# AT32A403Axx_v2 register map
Vendor: Keil; Series: AT32A403A; File version: 1.0
CPU: CM4 r0p1, little endian, no MPU, FPU, 4 interrupt priority bits
Registers are 32-bit, read-write, reset 0x0 unless marked. A register's access mark holds for its fields unless they carry their own. Offsets are from the block's base; [hi:lo] are bit positions; {n}, {i} and the like mark numbered series; 'fields as' and 'values as' point back to an identical list.

## CAN1 — Can controller area network
Base 0x40006400
Same registers: CAN2 0x40006800
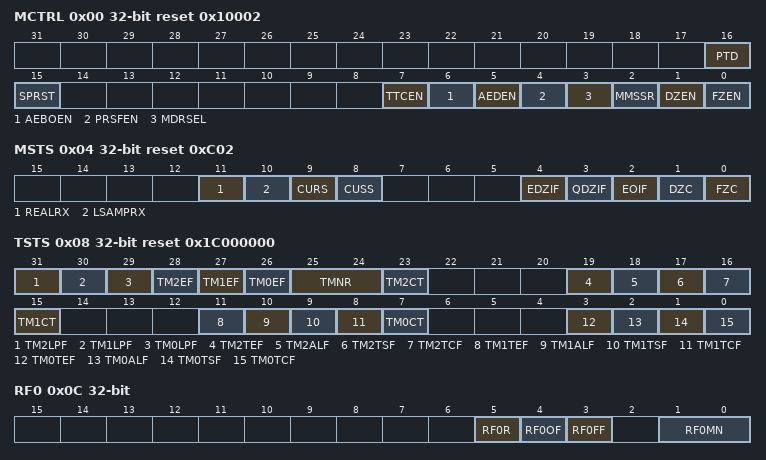
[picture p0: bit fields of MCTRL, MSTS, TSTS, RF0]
0x00 MCTRL reset 0x10002 — Main control register
  [16] PTD — Prohibit transmission when debug
  [15] SPRST — Software partial reset
  [7] TTCEN — Time triggered communication mode enable
  [6] AEBOEN — Automatic exit bus-off enable
  [5] AEDEN — Automatic exit doze mode enable
  [4] PRSFEN — Prohibit retransmission when sending fails enable
  [3] MDRSEL — Message discarding rule select when overflow
  [2] MMSSR — Multiple message sending sequence rule
  [1] DZEN — Doze mode enable
  [0] FZEN — Freeze mode enable
0x04 MSTS reset 0xC02 — Main status register
  [11] REALRX ro — Real time level of RX pin
  [10] LSAMPRX ro — Last sample level of RX pin
  [9] CURS ro — Currently receiving status
  [8] CUSS ro — Currently sending status
  [4] EDZIF — Enter doze mode interrupt flag
  [3] QDZIF — Quit doze mode interrupt flag
  [2] EOIF — Error occur Interrupt flag
  [1] DZC ro — Doze mode confirm
  [0] FZC ro — Freeze mode confirm
0x08 TSTS reset 0x1C000000 — Transmit status register
  [31] TM2LPF ro — Transmit mailbox 2 lowest priority flag
  [30] TM1LPF ro — Transmit mailbox 1 lowest priority flag
  [29] TM0LPF ro — Transmit mailbox 0 lowest priority flag
  [28] TM2EF ro — Transmit mailbox 2 empty flag
  [27] TM1EF ro — Transmit mailbox 1 empty flag
  [26] TM0EF ro — Transmit mailbox 0 empty flag
  [25:24] TMNR ro — Transmit Mailbox number record
  [23] TM2CT — Transmit mailbox 2 cancel transmission
  [19] TM2TEF — Transmit mailbox 2 transmission error flag
  [18] TM2ALF — Transmit mailbox 2 arbitration lost flag
  [17] TM2TSF — Transmit mailbox 2 transmission success flag
  [16] TM2TCF — transmit mailbox 2 transmission complete flag
  [15] TM1CT — Transmit mailbox 1 cancel transmission
  [11] TM1TEF — Transmit mailbox 1 transmission error flag
  [10] TM1ALF — Transmit mailbox 1 arbitration lost flag
  [9] TM1TSF — Transmit mailbox 1 transmission success flag
  [8] TM1TCF — Transmit mailbox 1 transmission complete flag
  [7] TM0CT — Transmit mailbox 0 cancel transmission
  [3] TM0TEF — Transmit mailbox 0 transmission error flag
  [2] TM0ALF — Transmit mailbox 0 arbitration lost flag
  [1] TM0TSF — Transmit mailbox 0 transmission success flag
  [0] TM0TCF — Transmit mailbox 0 transmission complete flag
0x0C RF0 — Receive FIFO 0 register
  [5] RF0R — Receive FIFO 0 release
  [4] RF0OF — Receive FIFO 0 overflow flag
  [3] RF0FF — Receive FIFO 0 full flag
  [1:0] RF0MN ro — Receive FIFO 0 message num
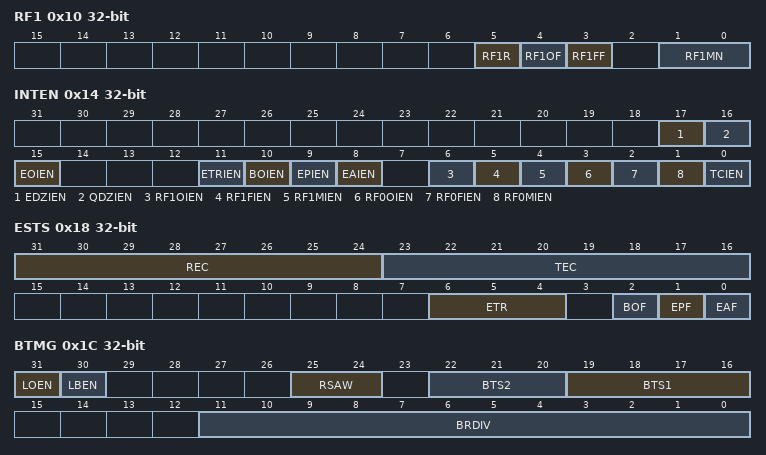
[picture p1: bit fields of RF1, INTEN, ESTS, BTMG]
0x10 RF1 — Receive FIFO 1 register
  [5] RF1R — Receive FIFO 1 release
  [4] RF1OF — Receive FIFO 1 overflow flag
  [3] RF1FF — Receive FIFO 1 full flag
  [1:0] RF1MN ro — Receive FIFO 1 message num
0x14 INTEN — Interrupt enable register
  [17] EDZIEN — Enter doze mode interrupt enable
  [16] QDZIEN — Quit doze mode interrupt enable
  [15] EOIEN — Error occur interrupt enable
  [11] ETRIEN — Error type record interrupt enable
  [10] BOIEN — Bus-off interrupt enable
  [9] EPIEN — Error passive interrupt enable
  [8] EAIEN — Error active interrupt enable
  [6] RF1OIEN — Receive FIFO 1 overflow interrupt enable
  [5] RF1FIEN — Receive FIFO 1 full interrupt enable
  [4] RF1MIEN — FIFO 1 receive message interrupt enable
  [3] RF0OIEN — Receive FIFO 0 overflow interrupt enable
  [2] RF0FIEN — Receive FIFO 0 full interrupt enable
  [1] RF0MIEN — FIFO 0 receive message interrupt enable
  [0] TCIEN — Transmission complete interrupt enable
0x18 ESTS — Error status register
  [31:24] REC ro — Receive error counter
  [23:16] TEC ro — Transmit error counter
  [6:4] ETR — Error type record
  [2] BOF ro — Bus-off flag
  [1] EPF ro — Error passive flag
  [0] EAF ro — Error active flag
0x1C BTMG — Bit timing register
  [31] LOEN — Listen-Only mode
  [30] LBEN — Loop back mode
  [25:24] RSAW — Resynchronization adjust width
  [22:20] BTS2 — Bit time segment 2
  [19:16] BTS1 — Bit time segment 1
  [11:0] BRDIV — Baud rate division
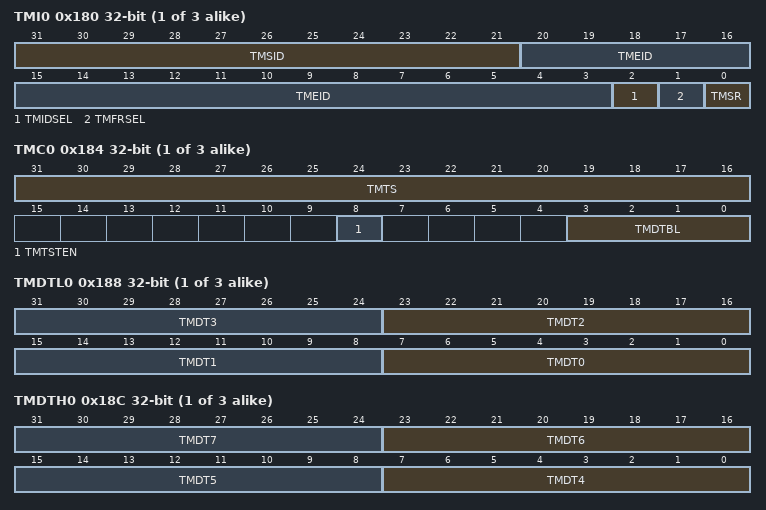
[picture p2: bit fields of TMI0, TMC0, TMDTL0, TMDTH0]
{0x180+0x10*i} TMI{i} (i=0..2) — Transmit mailbox {i} identifier register
  [31:21] TMSID — Transmit mailbox standard identifier or extended identifier high bytes
  [20:3] TMEID — Ttransmit mailbox extended identifier
  [2] TMIDSEL — Transmit mailbox identifier type select
  [1] TMFRSEL — Transmit mailbox frame type select
  [0] TMSR — Transmit mailbox send request
{0x184+0x10*i} TMC{i} (i=0..2) — Transmit mailbox {i} data length and time stamp register
  [31:16] TMTS — Transmit mailbox time stamp
  [8] TMTSTEN — Transmit mailbox time stamp transmit enable
  [3:0] TMDTBL — Transmit mailbox data byte length
{0x188+0x10*i} TMDTL{i} (i=0..2) — Transmit mailbox {i} low byte data register
  [8n+7:8n] TMDT{n} (n=0..3) — Transmit mailbox data byte {n}
{0x18C+0x10*i} TMDTH{i} (i=0..2) — Transmit mailbox {i} high byte data register
  [8n-25:8n-32] TMDT{n} (n=4..7) — Transmit mailbox data byte {n}
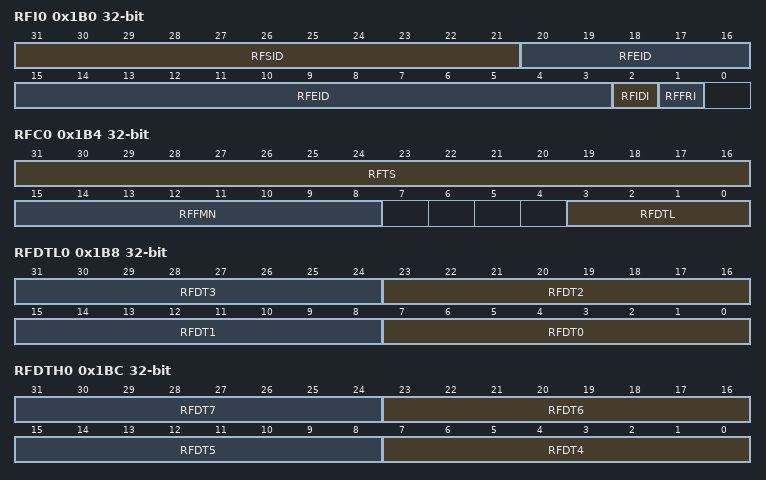
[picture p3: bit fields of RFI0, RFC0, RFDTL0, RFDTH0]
0x1B0 RFI0 ro — Receive FIFO 0 register
  [31:21] RFSID — Receive FIFO standard identifier or receive FIFO extended identifier
  [20:3] RFEID — Receive FIFO extended identifier
  [2] RFIDI — Receive FIFO identifier type indication
  [1] RFFRI — Receive FIFO frame type indication
0x1B4 RFC0 ro — Receive FIFO 0 data length and time stamp register
  [31:16] RFTS — Receive FIFO time stamp
  [15:8] RFFMN — Receive FIFO filter match number
  [3:0] RFDTL — Receive FIFO data length
0x1B8 RFDTL0 ro — Receive FIFO 0 low byte data register
  [8n+7:8n] RFDT{n} (n=0..3) — Receive FIFO data byte {n}
0x1BC RFDTH0 ro — Receive FIFO 0 high byte data register
  [8n-25:8n-32] RFDT{n} (n=4..7) — Receive FIFO data byte {n}
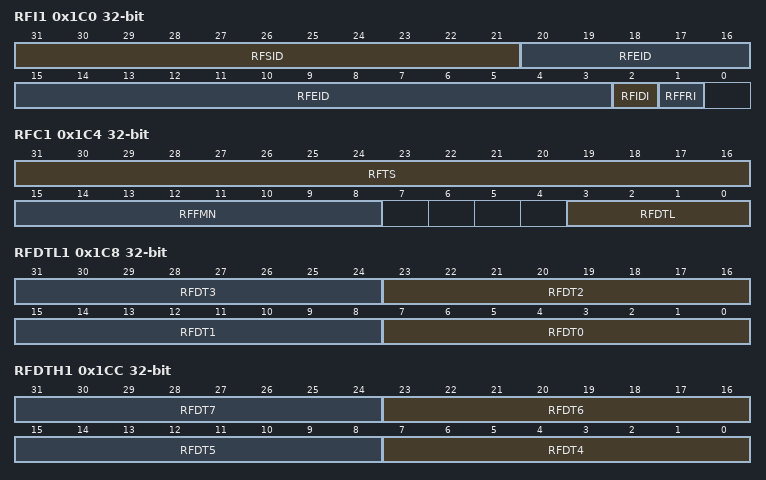
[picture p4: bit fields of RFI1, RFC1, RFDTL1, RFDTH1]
0x1C0 RFI1 ro — Receive FIFO 1 register
  fields as RFI0
0x1C4 RFC1 ro — Receive FIFO 1 data length and time stamp register
  fields as RFC0
0x1C8 RFDTL1 ro — Receive FIFO 1 low byte data register
  [8n+7:8n] RFDT{n} (n=0..3) — Receive FIFO data byte {n}
0x1CC RFDTH1 ro — Receive FIFO 1 high byte data register
  [8n-25:8n-32] RFDT{n} (n=4..7) — Receive FIFO data byte {n}
0x200 FCTRL — Filter control register
  [0] FCS — Filters configure switch
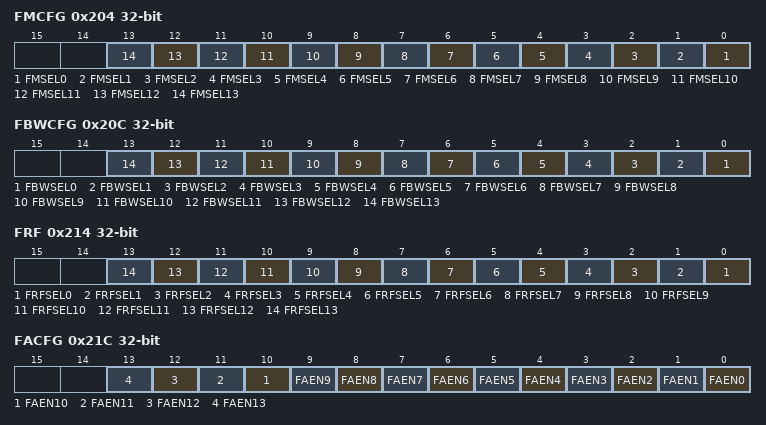
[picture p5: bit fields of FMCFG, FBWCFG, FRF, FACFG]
0x204 FMCFG — Filter mode config register
  [n] FMSEL{n} (n=0..13) — Filter mode select
0x20C FBWCFG — Filter bit width config register
  [n] FBWSEL{n} (n=0..13) — Filter bit width select
0x214 FRF — Filter related FIFO register
  [n] FRFSEL{n} (n=0..13) — Filter relation FIFO select
0x21C FACFG — Filter activate configuration register
  [n] FAEN{n} (n=0..13) — Filter activate enable
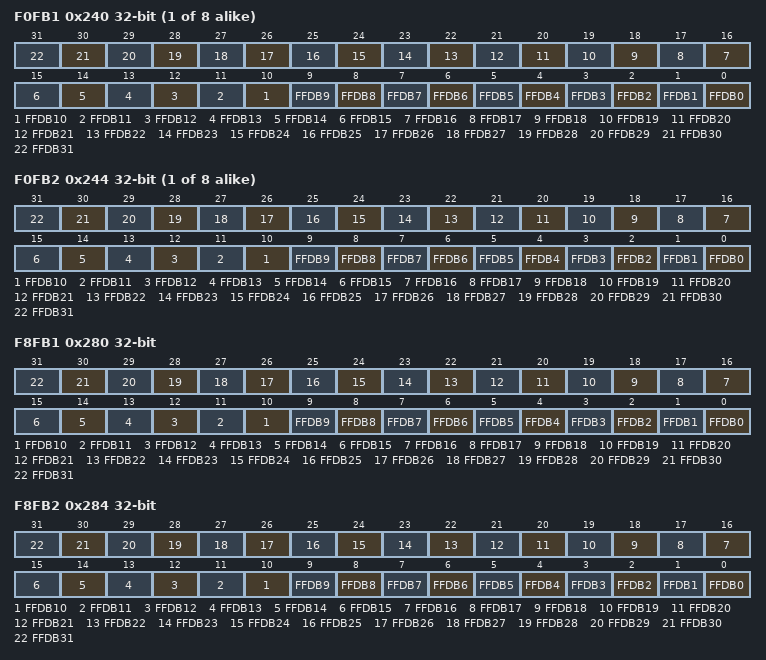
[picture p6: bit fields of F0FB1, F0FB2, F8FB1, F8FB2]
{0x240+8i} F{i}FB1 (i=0..7) — Filter bank {i} filtrate bit register 1
  [n] FFDB{n} (n=0..31) — Filter data bit
{0x244+8i} F{i}FB2 (i=0..7) — Filter bank {i} filtrate bit register 2
  [n] FFDB{n} (n=0..31) — Filter data bit
0x280 F8FB1 — Filter bank 8 filtrate bit filtrate bit register 1
  [n] FFDB{n} (n=0..31) — Filter data bit
0x284 F8FB2 — Filter bank 8 filtrate bit filtrate bit register 2
  [n] FFDB{n} (n=0..31) — Filter data bit
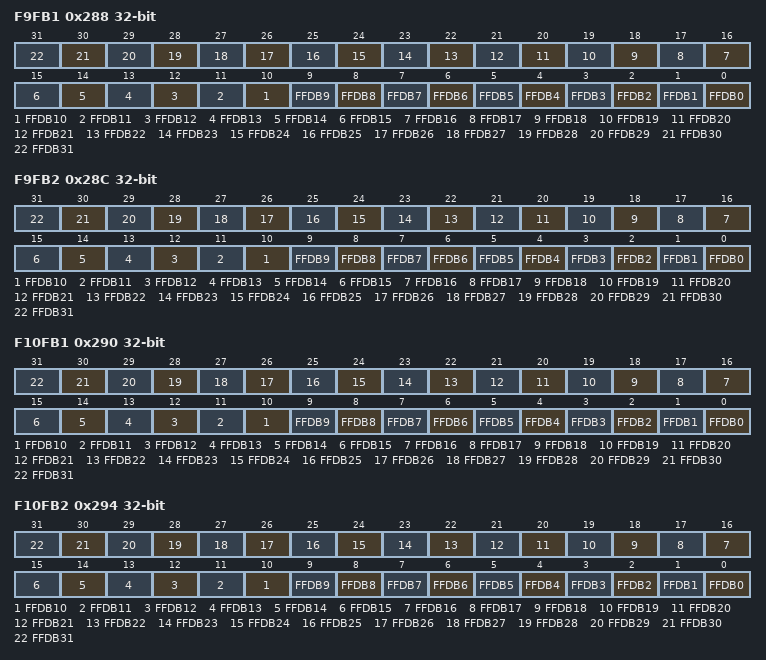
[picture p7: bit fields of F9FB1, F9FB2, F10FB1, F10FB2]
0x288 F9FB1 — Filter bank 9 filtrate bit filtrate bit filtrate bit filtrate bit filtrate bit register 1
  [n] FFDB{n} (n=0..31) — Filter data bit
0x28C F9FB2 — Filter bank 9 filtrate bit filtrate bit filtrate bit filtrate bit filtrate bit register 2
  [n] FFDB{n} (n=0..31) — Filter data bit
0x290 F10FB1 — Filter bank 10 filtrate bit register 1
  [n] FFDB{n} (n=0..31) — Filter data bit
0x294 F10FB2 — Filter bank 10 filtrate bit register 2
  [n] FFDB{n} (n=0..31) — Filter data bit
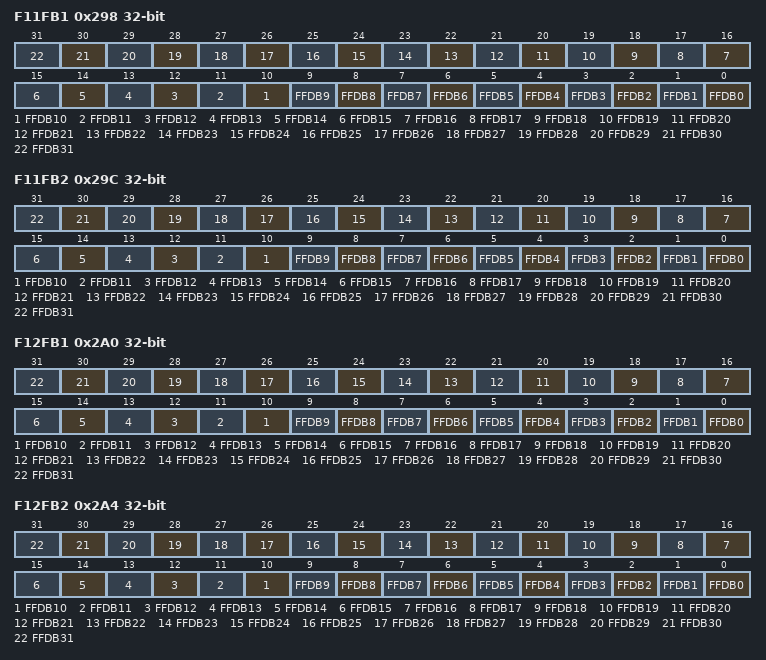
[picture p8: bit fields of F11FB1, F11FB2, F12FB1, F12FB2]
0x298 F11FB1 — Filter bank 11 filtrate bit register 1
  [n] FFDB{n} (n=0..31) — Filter data bit
0x29C F11FB2 — Filter bank 11 filtrate bit register 2
  [n] FFDB{n} (n=0..31) — Filter data bit
0x2A0 F12FB1 — Filter bank 12 filtrate bit filtrate bit register 1
  [n] FFDB{n} (n=0..31) — Filter data bit
0x2A4 F12FB2 — Filter bank 12 filtrate bit filtrate bit register 2
  [n] FFDB{n} (n=0..31) — Filter data bit
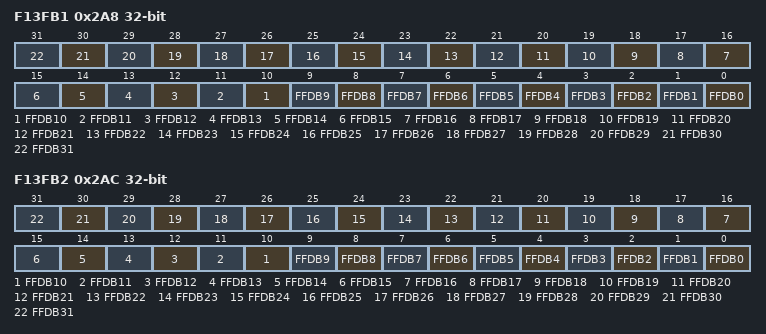
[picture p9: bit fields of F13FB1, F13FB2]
0x2A8 F13FB1 — Filter bank 13 filtrate bit filtrate bit register 1
  [n] FFDB{n} (n=0..31) — Filter data bit
0x2AC F13FB2 — Filter bank 13 filtrate bit filtrate bit register 2
  [n] FFDB{n} (n=0..31) — Filter data bit

## Notices in the file
Copyright (C) 2012-2014 ARM Limited. All rights reserved.
Purpose: System Viewer Description (SVD) Example (Schema Version 1.1)
This is a description of a none-existent and incomplete device
for demonstration purposes only.
Redistribution and use in source and binary forms, with or without
modification, are permitted provided that the following conditions are met:
- Redistributions of source code must retain the above copyright
notice, this list of conditions and the following disclaimer.
- Redistributions in binary form must reproduce the above copyright
notice, this list of conditions and the following disclaimer in the
documentation and/or other materials provided with the distribution.
- Neither the name of ARM nor the names of its contributors may be used
to endorse or promote products derived from this software without
specific prior written permission.
THIS SOFTWARE IS PROVIDED BY THE COPYRIGHT HOLDERS AND CONTRIBUTORS "AS IS"
AND ANY EXPRESS OR IMPLIED WARRANTIES, INCLUDING, BUT NOT LIMITED TO, THE
IMPLIED WARRANTIES OF MERCHANTABILITY AND FITNESS FOR A PARTICULAR PURPOSE
ARE DISCLAIMED. IN NO EVENT SHALL COPYRIGHT HOLDERS AND CONTRIBUTORS BE
LIABLE FOR ANY DIRECT, INDIRECT, INCIDENTAL, SPECIAL, EXEMPLARY, OR
CONSEQUENTIAL DAMAGES (INCLUDING, BUT NOT LIMITED TO, PROCUREMENT OF
SUBSTITUTE GOODS OR SERVICES; LOSS OF USE, DATA, OR PROFITS; OR BUSINESS
INTERRUPTION) HOWEVER CAUSED AND ON ANY THEORY OF LIABILITY, WHETHER IN
CONTRACT, STRICT LIABILITY, OR TORT (INCLUDING NEGLIGENCE OR OTHERWISE)
ARISING IN ANY WAY OUT OF THE USE OF THIS SOFTWARE, EVEN IF ADVISED OF THE
POSSIBILITY OF SUCH DAMAGE.
